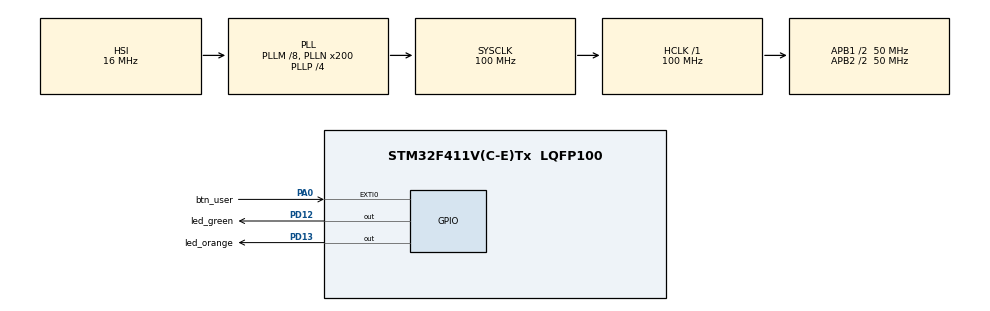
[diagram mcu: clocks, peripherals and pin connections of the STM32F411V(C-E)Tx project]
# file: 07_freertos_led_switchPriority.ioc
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Mcu.Family=STM32F4
Mcu.Name=STM32F411V(C-E)Tx
Mcu.Package=LQFP100
NVIC.EXTI0_IRQn=true\:0\:0\:false\:false\:true\:true\:true
NVIC.PriorityGroup=NVIC_PRIORITYGROUP_4
NVIC.TIM5_IRQn=true\:0\:0\:false\:false\:true\:false\:true
NVIC.TimeBase=TIM5_IRQn
NVIC.TimeBaseIP=TIM5
PA0-WKUP.GPIO_Label=btn_user
PA0-WKUP.Signal=GPXTI0
PD12.GPIO_Label=led_green
PD12.Signal=GPIO_Output
PD13.GPIO_Label=led_orange
PD13.Signal=GPIO_Output
ProjectManager.HeapSize=0x200
ProjectManager.StackSize=0x400
ProjectManager.TargetToolchain=STM32CubeIDE
RCC.48MHZClocksFreq_Value=50000000
RCC.AHBFreq_Value=100000000
RCC.APB1CLKDivider=RCC_HCLK_DIV2
RCC.APB1Freq_Value=50000000
RCC.APB1TimFreq_Value=100000000
RCC.APB2CLKDivider=RCC_HCLK_DIV2
RCC.APB2Freq_Value=50000000
RCC.APB2TimFreq_Value=100000000
RCC.CortexFreq_Value=100000000
RCC.HCLKFreq_Value=100000000
RCC.HSE_VALUE=8000000
RCC.HSI_VALUE=16000000
RCC.LSE_VALUE=32768
RCC.PLLI2SM=5
RCC.PLLI2SN=200
RCC.PLLM=8
RCC.PLLN=200
RCC.PLLP=RCC_PLLP_DIV4
RCC.PLLQ=8
RCC.SYSCLKFreq_VALUE=100000000
RCC.SYSCLKSource=RCC_SYSCLKSOURCE_PLLCLK
RCC.VCOOutputFreq_Value=400000000
VP_SYS_VS_tim5.Mode=TIM5
board=STM32F411E-DISCO

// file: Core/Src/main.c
/* USER CODE BEGIN Header */
/**
 ******************************************************************************
 * @file           : main.c
 * @brief          : Main program body
 ******************************************************************************
 * @attention
 *
 * Copyright (c) 2023 STMicroelectronics.
 * All rights reserved.
 *
 * This software is licensed under terms that can be found in the LICENSE file
 * in the root directory of this software component.
 * If no LICENSE file comes with this software, it is provided AS-IS.
 *
 ******************************************************************************
 */
/* USER CODE END Header */
#include "main.h"

/* USER CODE BEGIN Includes */

#include "FreeRTOS.h"
#include "task.h"
/* USER CODE END Includes */

/* USER CODE BEGIN PV */
#define DWT_CTRL    (*(volatile uint32_t*)0xE0001000)

/* USER CODE END PV */

void SystemClock_Config(void);
static void MX_GPIO_Init(void);
/* USER CODE BEGIN PFP */
static void task_led_green(void *parameter);
static void task_led_orange(void *parameter);

void switch_priority(void);
void btn_isr_handle(void);
TaskHandle_t taskHandle_led_green;
TaskHandle_t taskHandle_led_orange;

TaskHandle_t taskHandle_btn;

volatile TaskHandle_t next_task_handle = NULL;
volatile BaseType_t status_button = 0;

/* USER CODE END PFP */

/* USER CODE BEGIN 0 */

extern void SEGGER_UART_init(uint32_t);

/* USER CODE END 0 */

int main(void) {
	/* USER CODE BEGIN 1 */
	BaseType_t status;

	/* USER CODE END 1 */

	/* MCU Configuration--------------------------------------------------------*/

	/* Reset of all peripherals, Initializes the Flash interface and the Systick. */
	HAL_Init();

	/* Configure the system clock */
	SystemClock_Config();

	/* Initialize all configured peripherals */
	MX_GPIO_Init();
	/* USER CODE BEGIN 2 */
	//Enable the CYCCNT counter.
	DWT_CTRL |= (1 << 0);

	SEGGER_SYSVIEW_Conf();
	SEGGER_SYSVIEW_Start();

  	SEGGER_UART_init(500000);

	/*
	 * 		LED
	 *
	 *
	 *
	 * */
	status = xTaskCreate(task_led_green, "led_green", 200, NULL, 2,
			&taskHandle_led_green);

	configASSERT(status == pdPASS);

	status = xTaskCreate(task_led_orange, "led_orange", 200, NULL, 3,
			&taskHandle_led_orange);

	configASSERT(status == pdPASS);

	vTaskStartScheduler();
	/* USER CODE END 2 */

	/* Infinite loop */
	while (1) {

	}
}

void SystemClock_Config(void) {
	RCC_OscInitTypeDef RCC_OscInitStruct = { 0 };
	RCC_ClkInitTypeDef RCC_ClkInitStruct = { 0 };

	/** Configure the main internal regulator output voltage
	 */
	__HAL_RCC_PWR_CLK_ENABLE();
	__HAL_PWR_VOLTAGESCALING_CONFIG(PWR_REGULATOR_VOLTAGE_SCALE1);
	/** Initializes the RCC Oscillators according to the specified parameters
	 * in the RCC_OscInitTypeDef structure.
	 */
	RCC_OscInitStruct.OscillatorType = RCC_OSCILLATORTYPE_HSI;
	RCC_OscInitStruct.HSIState = RCC_HSI_ON;
	RCC_OscInitStruct.HSICalibrationValue = RCC_HSICALIBRATION_DEFAULT;
	RCC_OscInitStruct.PLL.PLLState = RCC_PLL_ON;
	RCC_OscInitStruct.PLL.PLLSource = RCC_PLLSOURCE_HSI;
	RCC_OscInitStruct.PLL.PLLM = 8;
	RCC_OscInitStruct.PLL.PLLN = 200;
	RCC_OscInitStruct.PLL.PLLP = RCC_PLLP_DIV4;
	RCC_OscInitStruct.PLL.PLLQ = 8;
	if (HAL_RCC_OscConfig(&RCC_OscInitStruct) != HAL_OK) {
		Error_Handler();
	}
	/** Initializes the CPU, AHB and APB buses clocks
	 */
	RCC_ClkInitStruct.ClockType = RCC_CLOCKTYPE_HCLK | RCC_CLOCKTYPE_SYSCLK
			| RCC_CLOCKTYPE_PCLK1 | RCC_CLOCKTYPE_PCLK2;
	RCC_ClkInitStruct.SYSCLKSource = RCC_SYSCLKSOURCE_PLLCLK;
	RCC_ClkInitStruct.AHBCLKDivider = RCC_SYSCLK_DIV1;
	RCC_ClkInitStruct.APB1CLKDivider = RCC_HCLK_DIV2;
	RCC_ClkInitStruct.APB2CLKDivider = RCC_HCLK_DIV2;

	if (HAL_RCC_ClockConfig(&RCC_ClkInitStruct, FLASH_LATENCY_3) != HAL_OK) {
		Error_Handler();
	}
}

static void MX_GPIO_Init(void) {
	GPIO_InitTypeDef GPIO_InitStruct = { 0 };

	/* GPIO Ports Clock Enable */
	__HAL_RCC_GPIOA_CLK_ENABLE();
	__HAL_RCC_GPIOD_CLK_ENABLE();

	/*Configure GPIO pin Output Level */
	HAL_GPIO_WritePin(GPIOD, led_green_Pin | led_orange_Pin, GPIO_PIN_RESET);

	/*Configure GPIO pin : btn_user_Pin */
	GPIO_InitStruct.Pin = btn_user_Pin;
	GPIO_InitStruct.Mode = GPIO_MODE_IT_RISING;
	GPIO_InitStruct.Pull = GPIO_NOPULL;
	HAL_GPIO_Init(btn_user_GPIO_Port, &GPIO_InitStruct);

	/*Configure GPIO pins : led_green_Pin led_orange_Pin */
	GPIO_InitStruct.Pin = led_green_Pin | led_orange_Pin;
	GPIO_InitStruct.Mode = GPIO_MODE_OUTPUT_PP;
	GPIO_InitStruct.Pull = GPIO_NOPULL;
	GPIO_InitStruct.Speed = GPIO_SPEED_FREQ_LOW;
	HAL_GPIO_Init(GPIOD, &GPIO_InitStruct);

	/* EXTI interrupt init*/
	HAL_NVIC_SetPriority(EXTI0_IRQn, 0, 0);
	HAL_NVIC_EnableIRQ(EXTI0_IRQn);

}

/* USER CODE BEGIN 4 */
static void task_led_green(void *parameter) {
	while (1) {
		HAL_GPIO_TogglePin(GPIOD, led_green_Pin);
		HAL_Delay(1000);
		switch_priority();
	}
}

static void task_led_orange(void *parameter) {

	while (1) {
		HAL_GPIO_TogglePin(GPIOD, led_orange_Pin);
		HAL_Delay(500);
		switch_priority();
	}
}

void btn_isr_handle(void) {

	traceISR_ENTER();
	status_button = 1;
	traceISR_EXIT();
}

void switch_priority(void) {
	UBaseType_t p1, p2;
	xTaskHandle t1, t2, curr;

	BaseType_t switch_priority = 0;

	portENTER_CRITICAL();
	if (status_button) {
		status_button = 0;
		switch_priority = 1;
	}
	portEXIT_CRITICAL();

	if (switch_priority) {
		t1 = xTaskGetHandle("led_green");
		t2 = xTaskGetHandle("led_orange");

		p1 = uxTaskPriorityGet(t1);
		p2 = uxTaskPriorityGet(t2);

		curr = xTaskGetCurrentTaskHandle();

		if (curr == t1) {
			vTaskPrioritySet(t1, p2);
			vTaskPrioritySet(t2, p1);
		} else {
			vTaskPrioritySet(t2, p1);
			vTaskPrioritySet(t1, p2);
		}
	}

}
/* USER CODE END 4 */

void HAL_TIM_PeriodElapsedCallback(TIM_HandleTypeDef *htim) {
	if (htim->Instance == TIM5) {
		HAL_IncTick();
	}
}

void Error_Handler(void) {
	__disable_irq();
	while (1) {
	}
}
